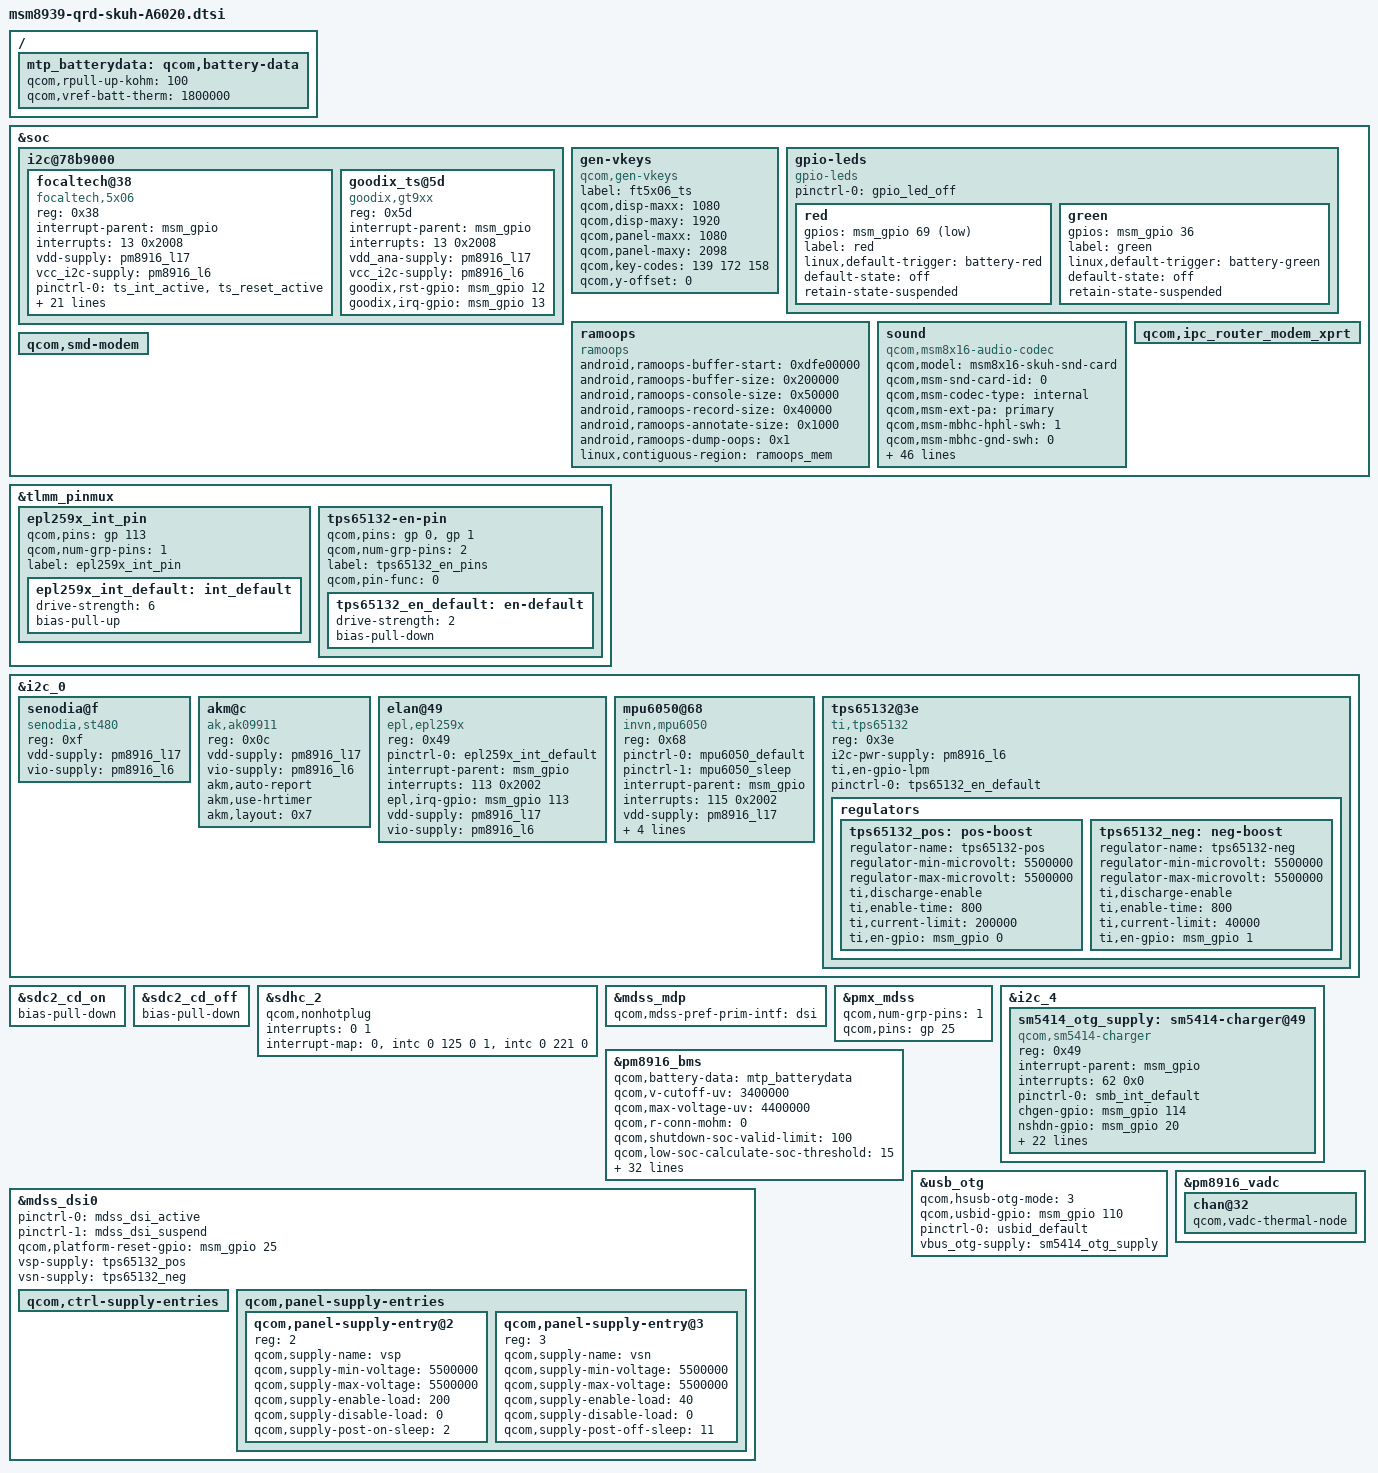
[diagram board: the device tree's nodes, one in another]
/* Copyright (c) 2017, The Linux Foundation. All rights reserved.
 *
 * This program is free software; you can redistribute it and/or modify
 * it under the terms of the GNU General Public License version 2 and
 * only version 2 as published by the Free Software Foundation.
 *
 * This program is distributed in the hope that it will be useful,
 * but WITHOUT ANY WARRANTY; without even the implied warranty of
 * MERCHANTABILITY or FITNESS FOR A PARTICULAR PURPOSE.  See the
 * GNU General Public License for more details.
 */

&soc {
	i2c@78b9000 { /* BLSP1 QUP5 */
		focaltech@38 {
			compatible = "focaltech,5x06";
			reg = <0x38>;
			interrupt-parent = <&msm_gpio>;
			interrupts = <13 0x2008>;
			vdd-supply = <&pm8916_l17>;
			vcc_i2c-supply = <&pm8916_l6>;
			/* pins used by touchscreen */
			pinctrl-names = "pmx_ts_active","pmx_ts_suspend","pmx_ts_release";
			pinctrl-0 = <&ts_int_active &ts_reset_active>;
			pinctrl-1 = <&ts_int_suspend &ts_reset_suspend>;
			pinctrl-2 = <&ts_release>;
			focaltech,name = "ft5336";
			focaltech,family-id = <0x14>;
			focaltech,reset-gpio = <&msm_gpio 12 0x0>;
			focaltech,irq-gpio = <&msm_gpio 13 0x2008>;
			focaltech,button-map= <139 102 158>;
			focaltech,no-force-update;
			focaltech,i2c-pull-up;
			focaltech,group-id = <1>;
			focaltech,hard-reset-delay-ms = <20>;
			focaltech,soft-reset-delay-ms = <200>;
			focaltech,num-max-touches = <5>;
			focaltech,fw-delay-aa-ms = <30>;
			focaltech,fw-delay-55-ms = <30>;
			focaltech,fw-upgrade-id1 = <0x11>;
			focaltech,fw-upgrade-id2 = <0x11>;
			focaltech,fw-delay-readid-ms = <10>;
			focaltech,fw-delay-era-flsh-ms = <2000>;
			focaltech,fw-auto-cal;
			focaltech,ignore-id-check;
		};
	
		goodix_ts@5d {
			compatible = "goodix,gt9xx";
			reg = <0x5d>;
			interrupt-parent = <&msm_gpio>;
			interrupts = <13 0x2008>;
			vdd_ana-supply = <&pm8916_l17>;
			vcc_i2c-supply = <&pm8916_l6>;
			goodix,rst-gpio = <&msm_gpio 12 0x0>;
			goodix,irq-gpio = <&msm_gpio 13 0x2008>;
		};
	};

	gen-vkeys {
		compatible = "qcom,gen-vkeys";
		label = "ft5x06_ts";
		qcom,disp-maxx = <1080>;
		qcom,disp-maxy = <1920>;
		qcom,panel-maxx = <1080>;
		qcom,panel-maxy = <2098>;
		qcom,key-codes = <139 172 158>;
		qcom,y-offset = <0>;
	};

	gpio-leds {
		compatible = "gpio-leds";
		status = "okay";
		pinctrl-names = "default";
		pinctrl-0 = <&gpio_led_off>;

		red {
			gpios = <&msm_gpio 69 1>;
			label = "red";
			linux,default-trigger = "battery-red";
			default-state = "off";
			retain-state-suspended;
		};

		green {
			gpios = <&msm_gpio 36 0>;
			label = "green";
			linux,default-trigger = "battery-green";
			default-state = "off";
			retain-state-suspended;
		};
	};

	ramoops {
		compatible = "ramoops";
		status = "ok";

		android,ramoops-buffer-start = <0xdfe00000>;
		android,ramoops-buffer-size = <0x200000>;
		android,ramoops-console-size = <0x50000>;
		android,ramoops-record-size = <0x40000>;
		android,ramoops-annotate-size = <0x1000>;
		android,ramoops-dump-oops = <0x1>;
		linux,contiguous-region = <&ramoops_mem>;
	};

	sound {
		compatible = "qcom,msm8x16-audio-codec";
		qcom,model = "msm8x16-skuh-snd-card";
		qcom,msm-snd-card-id = <0>;
		qcom,msm-codec-type = "internal";
		qcom,msm-ext-pa = "primary";
		qcom,msm-mbhc-hphl-swh = <1>;
		qcom,msm-mbhc-gnd-swh = <0>;
		qcom,msm-micbias1-ext-cap;
		qcom,msm-hs-micbias-type = "internal";
		qcom,audio-routing =
			"RX_BIAS", "MCLK",
			"SPK_RX_BIAS", "MCLK",
			"INT_LDO_H", "MCLK",
			"MIC BIAS External", "Handset Mic",
			"MIC BIAS Internal2", "Headset Mic",
			"MIC BIAS External", "Secondary Mic",
			"AMIC1", "MIC BIAS External",
			"AMIC2", "MIC BIAS Internal2",
			"AMIC3", "MIC BIAS External";
		pinctrl-names = "cdc_lines_act",
				"cdc_lines_sus";
		pinctrl-0 = <&cdc_pdm_lines_act>;
		pinctrl-1 = <&cdc_pdm_lines_sus>;
		asoc-platform = <&pcm0>, <&pcm1>, <&voip>, <&voice>,
				<&loopback>, <&compress>, <&hostless>,
				<&afe>, <&lsm>, <&routing>, <&lpa>;
		asoc-platform-names = "msm-pcm-dsp.0", "msm-pcm-dsp.1",
				"msm-voip-dsp", "msm-pcm-voice", "msm-pcm-loopback",
				"msm-compress-dsp", "msm-pcm-hostless", "msm-pcm-afe",
				"msm-lsm-client", "msm-pcm-routing", "msm-pcm-lpa";
		asoc-cpu = <&dai_pri_auxpcm>, <&dai_hdmi>, <&dai_mi2s0>, <&dai_mi2s1>,
				<&dai_mi2s2>, <&dai_mi2s3>, <&sb_0_rx>, <&sb_0_tx>,
				<&sb_1_rx>, <&sb_1_tx>, <&sb_3_rx>, <&sb_3_tx>,
				<&sb_4_rx>, <&sb_4_tx>, <&sb_5_tx>, <&bt_sco_rx>,
				<&bt_sco_tx>,<&bt_a2dp_rx>,<&int_fm_rx>,<&int_fm_tx>,<&afe_pcm_rx>,
				<&afe_pcm_tx>, <&afe_proxy_rx>, <&afe_proxy_tx>,
				<&incall_record_rx>, <&incall_record_tx>, <&incall_music_rx>,
				<&incall_music_2_rx>;
		asoc-cpu-names = "msm-dai-q6-auxpcm.1", "msm-dai-q6-hdmi.8", "msm-dai-q6-mi2s.0",
				"msm-dai-q6-mi2s.1", "msm-dai-q6-mi2s.2",
				"msm-dai-q6-mi2s.3", "msm-dai-q6-dev.16384",
				"msm-dai-q6-dev.16385", "msm-dai-q6-dev.16386",
				"msm-dai-q6-dev.16387", "msm-dai-q6-dev.16390",
				"msm-dai-q6-dev.16391", "msm-dai-q6-dev.16392",
				"msm-dai-q6-dev.16393", "msm-dai-q6-dev.16395",
				"msm-dai-q6-dev.12288", "msm-dai-q6-dev.12289",
                                "msm-dai-q6-dev.12290",
				"msm-dai-q6-dev.12292", "msm-dai-q6-dev.12293",
				"msm-dai-q6-dev.224", "msm-dai-q6-dev.225",
				"msm-dai-q6-dev.241", "msm-dai-q6-dev.240",
				"msm-dai-q6-dev.32771", "msm-dai-q6-dev.32772",
				"msm-dai-q6-dev.32773", "msm-dai-q6-dev.32770";
		asoc-codec = <&stub_codec>, <&pm8916_tombak_dig>;
		asoc-codec-names = "msm-stub-codec.1", "tombak_codec";
	};

        qcom,ipc_router_modem_xprt {
		/delete-property/ qcom,disable-pil-loading;
        };

        qcom,smd-modem {
                /delete-property/ qcom,not-loadable;
        };
};

&tlmm_pinmux {
	epl259x_int_pin {
		qcom,pins = <&gp 113>;
		qcom,num-grp-pins = <1>;
		label = "epl259x_int_pin";
		epl259x_int_default: int_default {
			drive-strength = <6>;
			bias-pull-up;
		};
	};
};

&i2c_0 { /* BLSP1 QUP2 */
	senodia@f {
		compatible = "senodia,st480";
		reg = <0xf>;
		vdd-supply = <&pm8916_l17>;
		vio-supply = <&pm8916_l6>;
	};

	akm@c {
		compatible = "ak,ak09911";
		reg = <0x0c>;
		vdd-supply = <&pm8916_l17>;
		vio-supply = <&pm8916_l6>;
		akm,auto-report;
                akm,use-hrtimer;
                akm,layout = <0x7>;
	};	

	elan@49 {
		reg = <0x49>;
		compatible = "epl,epl259x";
		pinctrl-names = "default";
		pinctrl-0 = <&epl259x_int_default>;
		interrupt-parent = <&msm_gpio>;
		interrupts = <113 0x2002>;
		epl,irq-gpio  = <&msm_gpio 113 0x2002>;
		vdd-supply = <&pm8916_l17>;
		vio-supply = <&pm8916_l6>;
	};

	mpu6050@68 { /* Gyroscope and accelerometer sensor combo */
		compatible = "invn,mpu6050";
		reg = <0x68>;
		pinctrl-names = "mpu_default","mpu_sleep";
		pinctrl-0 = <&mpu6050_default>;
		pinctrl-1 = <&mpu6050_sleep>;
		interrupt-parent = <&msm_gpio>;
		interrupts = <115 0x2002>;
		vdd-supply = <&pm8916_l17>;
		vlogic-supply = <&pm8916_l16>;
		vi2c-supply = <&pm8916_l6>;
		invn,gpio-int = <&msm_gpio 115 0x2002>;
		invn,place = "Portrait Down Back Side";
	};
};

&sdc2_cd_on {
	/delete-property/ bias-pull-up;
	bias-pull-down;
};

&sdc2_cd_off {
	/delete-property/ bias-disable;
	bias-pull-down;
};

&sdhc_2 {
	qcom,nonhotplug;
	interrupts = <0 1>;
	interrupt-map = <0 &intc 0 125 0
		1 &intc 0 221 0>;
	interrupt-names = "hc_irq", "pwr_irq";
	/delete-property/ cd-gpios;
};

&mdss_mdp {
	qcom,mdss-pref-prim-intf = "dsi";
};

&pmx_mdss {
	qcom,num-grp-pins = <1>;
	qcom,pins = <&gp 25>;
};

&tlmm_pinmux {
	tps65132-en-pin {
		qcom,pins = <&gp 0>, <&gp 1>;
		qcom,num-grp-pins = <2>;
		label = "tps65132_en_pins";
		qcom,pin-func = <0>;

		tps65132_en_default: en-default {
			drive-strength = <2>;
			bias-pull-down;
		};
	};
};

&i2c_0 { /* BLSP1 QUP2 */
	tps65132@3e {
		compatible = "ti,tps65132";
		reg = <0x3e>;
		i2c-pwr-supply = <&pm8916_l6>;
		ti,en-gpio-lpm;
		pinctrl-names = "default";
		pinctrl-0 = <&tps65132_en_default>;

		regulators {
			tps65132_pos: pos-boost {
				regulator-name = "tps65132-pos";
				regulator-min-microvolt = <5500000>;
				regulator-max-microvolt = <5500000>;
				ti,discharge-enable;
				ti,enable-time = <800>;
				ti,current-limit = <200000>;
				ti,en-gpio = <&msm_gpio 0 0>;
			};

			tps65132_neg: neg-boost {
				regulator-name = "tps65132-neg";
				regulator-min-microvolt = <5500000>;
				regulator-max-microvolt = <5500000>;
				ti,discharge-enable;
				ti,enable-time = <800>;
				ti,current-limit = <40000>;
				ti,en-gpio = <&msm_gpio 1 0>;
			};
		};
	};
};

&i2c_4 {
	sm5414_otg_supply: sm5414-charger@49 {
        compatible = "qcom,sm5414-charger";
        reg = <0x49>;
        interrupt-parent = <&msm_gpio>;
		interrupts = <62 0x0>;
		pinctrl-names = "default";
        pinctrl-0 = <&smb_int_default>;
        chgen-gpio = <&msm_gpio 114 0x00>; // nCHGEN Pin: Temp GPIO NUMBER
        nshdn-gpio = <&msm_gpio 20 0x00>; // nSHDN Pin: Temp GPIO NUMBER    
        sm-irq-gpio = <&msm_gpio 62 0x0>;           
        qcom,float-voltage-mv = <4400>;
        qcom,iterm-ma = <100>;
        //qcom,recharge-mv = <50>;
        regulator-name = "sm5414_otg_vreg";
        qcom,thermal-mitigation = <1500 1000 800 600>; //<1500 1000 800 0>;
        qcom,fastchg-current-max-ma = <2000>;     
        //qcom,disable-apsd;
        qcom,bms-psy-name = "bms";
        qcom,iterm-disabled;
        qcom,bms-controlled-charging;
        qcom,chg-inhibit-disabled;
        qcom,chg-vadc = <&pm8916_vadc>;
        qcom,chg-adc_tm = <&pm8916_adc_tm>;    
        qcom,using-pmic-therm;
        qcom,bat-present-decidegc = <(300)>;    //Unit: 0.1 degree centigride    
    /*
     * Below properties are used for enable JEITA 
     */    
        qcom,hot-bat-decidegc = <515>;
        qcom,warm-bat-decidegc = <450>;
        qcom,cool-bat-decidegc = <150>;
        qcom,cold-bat-decidegc = <0>;
        qcom,warm-bat-ma = <1000>;
        qcom,cool-bat-ma = <800>;
        qcom,warm-bat-mv = <4225>;
        qcom,cool-bat-mv = <4325>;
        status = "ok";
	};
};

/ {
	mtp_batterydata: qcom,battery-data {
		qcom,rpull-up-kohm = <100>;
		qcom,vref-batt-therm = <1800000>;

		#include "batterydata-wingtech_Lenovo_BL259_4v40_2750mah.dtsi"
	};
};

&pm8916_bms {
	qcom,battery-data = <&mtp_batterydata>;
	//+Other_platform_modify 20150927 huangfusheng.wt add dts config from pm8916 
       	qcom,v-cutoff-uv = <3400000>;
	qcom,max-voltage-uv = <4400000>;
	qcom,r-conn-mohm = <0>;
	qcom,shutdown-soc-valid-limit = <100>;
	qcom,low-soc-calculate-soc-threshold = <15>;
	qcom,low-voltage-calculate-soc-ms = <1000>;
	qcom,low-soc-calculate-soc-ms = <5000>;
	qcom,calculate-soc-ms = <20000>;
	qcom,volatge-soc-timeout-ms = <60000>;
	qcom,low-voltage-threshold = <3450000>;
	qcom,s3-ocv-tolerence-uv = <1200>;
	qcom,s2-fifo-length = <5>;
	qcom,low-soc-fifo-length = <2>;
	qcom,bms-vadc = <&pm8916_vadc>;
	qcom,bms-adc_tm = <&pm8916_adc_tm>;
	qcom,pmic-revid = <&pm8916_revid>;

	qcom,force-s3-on-suspend;
	qcom,force-s2-in-charging;
	qcom,report-charger-eoc;
	qcom,resume-soc = <98>;
	
        qcom,warm-bat-temperature = <450>;
        qcom,cool-bat-temperature = <150>;
        qcom,warm-chg-full-term-current = <(-170000)> ;
        qcom,cool-chg-full-term-current = <(-170000)> ;
        qcom,normal-chg-full-term-current = <(-150000)>;

        qcom,warm-chg-full-term_vbat = <4120000>;
        qcom,cool-chg-full-term_vbat = <4230000>;
        qcom,normal-chg-full-term_vbat = <4350000>;

        qcom,warm-chg-full-term-ocv = <4100000> ;
        qcom,cool-chg-full-term-ocv = <4150000> ;
        qcom,normal-chg-full-term-ocv = <4330000>;

        qcom,cool-chg-full-term-soc = <80>;
	qcom,cool-chg-recharge-soc = <90>;
	qcom,warm-chg-full-term-soc = <78>;
	qcom,warm-chg-recharge-soc = <82>;
        qcom,current-report-eoc;
	qcom,use-reported-soc;
	status = "ok";
};

&mdss_dsi0 {
	pinctrl-names = "mdss_default", "mdss_sleep";
	pinctrl-0 = <&mdss_dsi_active>;
	pinctrl-1 = <&mdss_dsi_suspend>;
	qcom,platform-reset-gpio = <&msm_gpio 25 0>;
	//qcom,platform-bklight-en-gpio = <&msm_gpio 1 0>;
	vsp-supply = <&tps65132_pos>;
	vsn-supply = <&tps65132_neg>;

	qcom,ctrl-supply-entries {
		/delete-node/ qcom,ctrl-supply-entry@0;
	};

	qcom,panel-supply-entries {
		#address-cells = <1>;
		#size-cells = <0>;
		
		qcom,panel-supply-entry@2 {
			reg = <2>;
			qcom,supply-name = "vsp";
			qcom,supply-min-voltage = <5500000>;
			qcom,supply-max-voltage = <5500000>;
			qcom,supply-enable-load = <200>;
			qcom,supply-disable-load = <0>;
			qcom,supply-post-on-sleep = <2>;

		};

		qcom,panel-supply-entry@3 {
			reg = <3>;
			qcom,supply-name = "vsn";
			qcom,supply-min-voltage = <5500000>;
			qcom,supply-max-voltage = <5500000>;
			qcom,supply-enable-load = <40>;
			qcom,supply-disable-load = <0>;
			qcom,supply-post-off-sleep = <11>;
		};
	};
};

&usb_otg {
       qcom,hsusb-otg-mode = <3>;
       qcom,usbid-gpio = <&msm_gpio 110 0>;
       pinctrl-names = "default";
       pinctrl-0 = <&usbid_default>;
       vbus_otg-supply = <&sm5414_otg_supply>;
};

&pm8916_vadc {
	chan@32 {	
		qcom,vadc-thermal-node;
	};
};

